# LPC845 register map
Vendor: nxp.com; File version: 1.0
LPC845M301JBD48,LPC845M301JBD64,LPC845M301JHI33,LPC845M301JHI48
CPU: CM0PLUS r0p0, little endian, no MPU, no FPU, VTOR, 2 interrupt priority bits
Registers are 32-bit, read-write, reset 0x0 unless marked. A register's access mark holds for its fields unless they carry their own. Offsets are from the block's base; lines under a group give offsets from that group; [hi:lo] are bit positions; {n}, {i} and the like mark numbered series; 'fields as' and 'values as' point back to an identical list; <NAME> marks a mode.

## Memory map
0x40000000 WWDT size 0x1C — LPC84x Windowed Watchdog Timer (WWDT)
0x40004000 MRT0 size 0xFC — LPC84x Multi-Rate Timer (MRT)
0x40008000 WKT size 0x10 — LPC84x Wake Up Timer(WKT)
0x4000C000 SWM0 size 0x1C8 — LPC84x SWM
0x40014000 DAC0 size 0xC — LPC84x 10-bit DAC controller (DAC)
0x40018000 DAC1 size 0xC — LPC84x 10-bit DAC controller (DAC)
0x4001C000 ADC0 size 0x70 — LPC84x 12-bit ADC controller (ADC)
0x40020000 PMU size 0x18 — LPC84x PMU
0x40024000 ACOMP size 0x8 — LPC84x analog comparator
0x4002C000 INPUTMUX size 0xA4 — LPC84x Input multiplexing (INPUT MUX)
0x40030000 I2C2 size 0x84 — LPC84x I2C-bus interfaces
0x40034000 I2C3 size 0x84 — LPC84x I2C-bus interfaces
0x40038000 CTIMER0 size 0x88 — LPC184 Standard counter/timer
0x40040000 FLASH_CTRL size 0xFEC — LPC84x NVMC flash controller
0x40044000 IOCON size 0xE0 — LPC84x I/O pin configuration (IOCON)
0x40048000 SYSCON size 0x3FC — LPC84x System configuration (SYSCON)
0x40050000 I2C0 size 0x84 — LPC84x I2C-bus interfaces
0x40054000 I2C1 size 0x84 — LPC84x I2C-bus interfaces
0x40058000 SPI0 size 0x2C — LPC84x Serial Peripheral Interfaces (SPI)
0x4005C000 SPI1 size 0x2C — LPC84x Serial Peripheral Interfaces (SPI)
0x40060000 CAPT size 0x1000 — LPC84x Capacitive Touch
0x40064000 USART0 size 0x30 — LPC84x USARTs
0x40068000 USART1 size 0x30 — LPC84x USARTs
0x4006C000 USART2 size 0x30 — LPC84x USARTs
0x40070000 USART3 size 0x30 — LPC84x USARTs
0x40074000 USART4 size 0x30 — LPC84x USARTs
0x50000000 CRC size 0xC — LPC5411x CRC engine
0x50004000 SCT0 size 0x538 — LPC84x SCTimer/PWM (SCT)
0x50008000 DMA0 size 0x58C — LPC84x DMA controller
0x5000C000 MTB_SFR size 0x10 — LPC84x Micro Trace Buffer
0xA0000000 GPIO size 0x2488 — LPC84x General Purpose I/O (GPIO)
0xA0004000 PINT size 0x34 — LPC84x Pin interrupt and pattern match (PINT)

## Interrupts
0 SPI0
1 SPI1
2 DAC0
3 USART0
4 USART1
5 USART2
7 I2C1
8 I2C0
9 SCT0
10 MRT0
11 CMP_CAPT (ACOMP, CAPT)
12 WDT (WWDT)
13 BOD (SYSCON)
14 FLASH (FLASH_CTRL)
15 WKT
16 ADC0_SEQA (ADC0)
17 ADC0_SEQB (ADC0)
18 ADC0_THCMP (ADC0)
19 ADC0_OVR (ADC0)
20 DMA0
21 I2C2
22 I2C3
23 CTIMER0
24 PIN_INT0 (PINT)
25 PIN_INT1 (PINT)
26 PIN_INT2 (PINT)
27 PIN_INT3 (PINT)
28 PIN_INT4 (PINT)
29 PIN_INT5_DAC1 (PINT)
30 PIN_INT6_USART3 (PINT)
31 PIN_INT7_USART4 (PINT)

## WWDT — LPC84x Windowed Watchdog Timer (WWDT)
Base 0x40000000
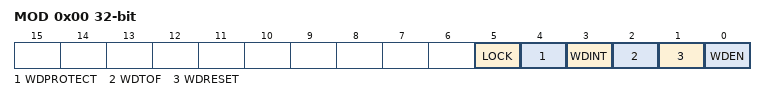
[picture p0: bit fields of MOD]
0x00 MOD — Watchdog mode register. This register contains the basic mode and status of the Watchdog Timer.
  [5] LOCK — Once this bit is set to one and a watchdog feed is performed, disabling or powering down the watchdog oscillator is prevented by hardware. This bit can be set once by software and is only cleared by any reset.
  [4] WDPROTECT — Watchdog update mode. This bit can be set once by software and is only cleared by a reset.
    0=FLEXIBLE (Flexible. The watchdog time-out value (TC) can be changed at any time.); 1=THRESHOLD (Threshold. The watchdog time-out value (TC) can be changed only after the counter is below the value of WDWARNINT and WDWINDOW.)
  [3] WDINT — Warning interrupt flag. Set when the timer is at or below the value in WDWARNINT. Cleared by software writing a 1 to this bit position. Note that this bit cannot be cleared while the WARNINT value is equal to the value of the TV register. This can occur if the value of WARNINT is 0 and the WDRESET bit is 0 when TV decrements to 0.
  [2] WDTOF — Watchdog time-out flag. Set when the watchdog timer times out, by a feed error, or by events associated with WDPROTECT. Cleared by software writing a 0 to this bit position. Causes a chip reset if WDRESET = 1.
  [1] WDRESET — Watchdog reset enable bit. Once this bit has been written with a 1 it cannot be re-written with a 0.
    0=INTERRUPT (Interrupt. A watchdog time-out will not cause a chip reset.); 1=RESET (Reset. A watchdog time-out will cause a chip reset.)
  [0] WDEN — Watchdog enable bit. Once this bit is set to one and a watchdog feed is performed, the watchdog timer will run permanently.
    0=STOP (Stop. The watchdog timer is stopped.); 1=RUN (Run. The watchdog timer is running.)
0x04 TC reset 0xFF — Watchdog timer constant register. This 24-bit register determines the time-out value.
  [23:0] COUNT — Watchdog time-out value.
0x08 FEED wo reset not defined — Watchdog feed sequence register. Writing 0xAA followed by 0x55 to this register reloads the Watchdog timer with the value contained in TC.
  [7:0] FEED — Feed value should be 0xAA followed by 0x55.
0x0C TV ro reset 0xFF — Watchdog timer value register. This 24-bit register reads out the current value of the Watchdog timer.
  [23:0] COUNT — Counter timer value.
0x14 WARNINT — Watchdog Warning Interrupt compare value.
  [9:0] WARNINT — Watchdog warning interrupt compare value.
0x18 WINDOW reset 0xFFFFFF — Watchdog Window compare value.
  [23:0] WINDOW — Watchdog window value.

## Licence text in the file
Copyright 2016-2019 NXP All rights reserved. SPDX-License-Identifier: BSD-3-Clause
